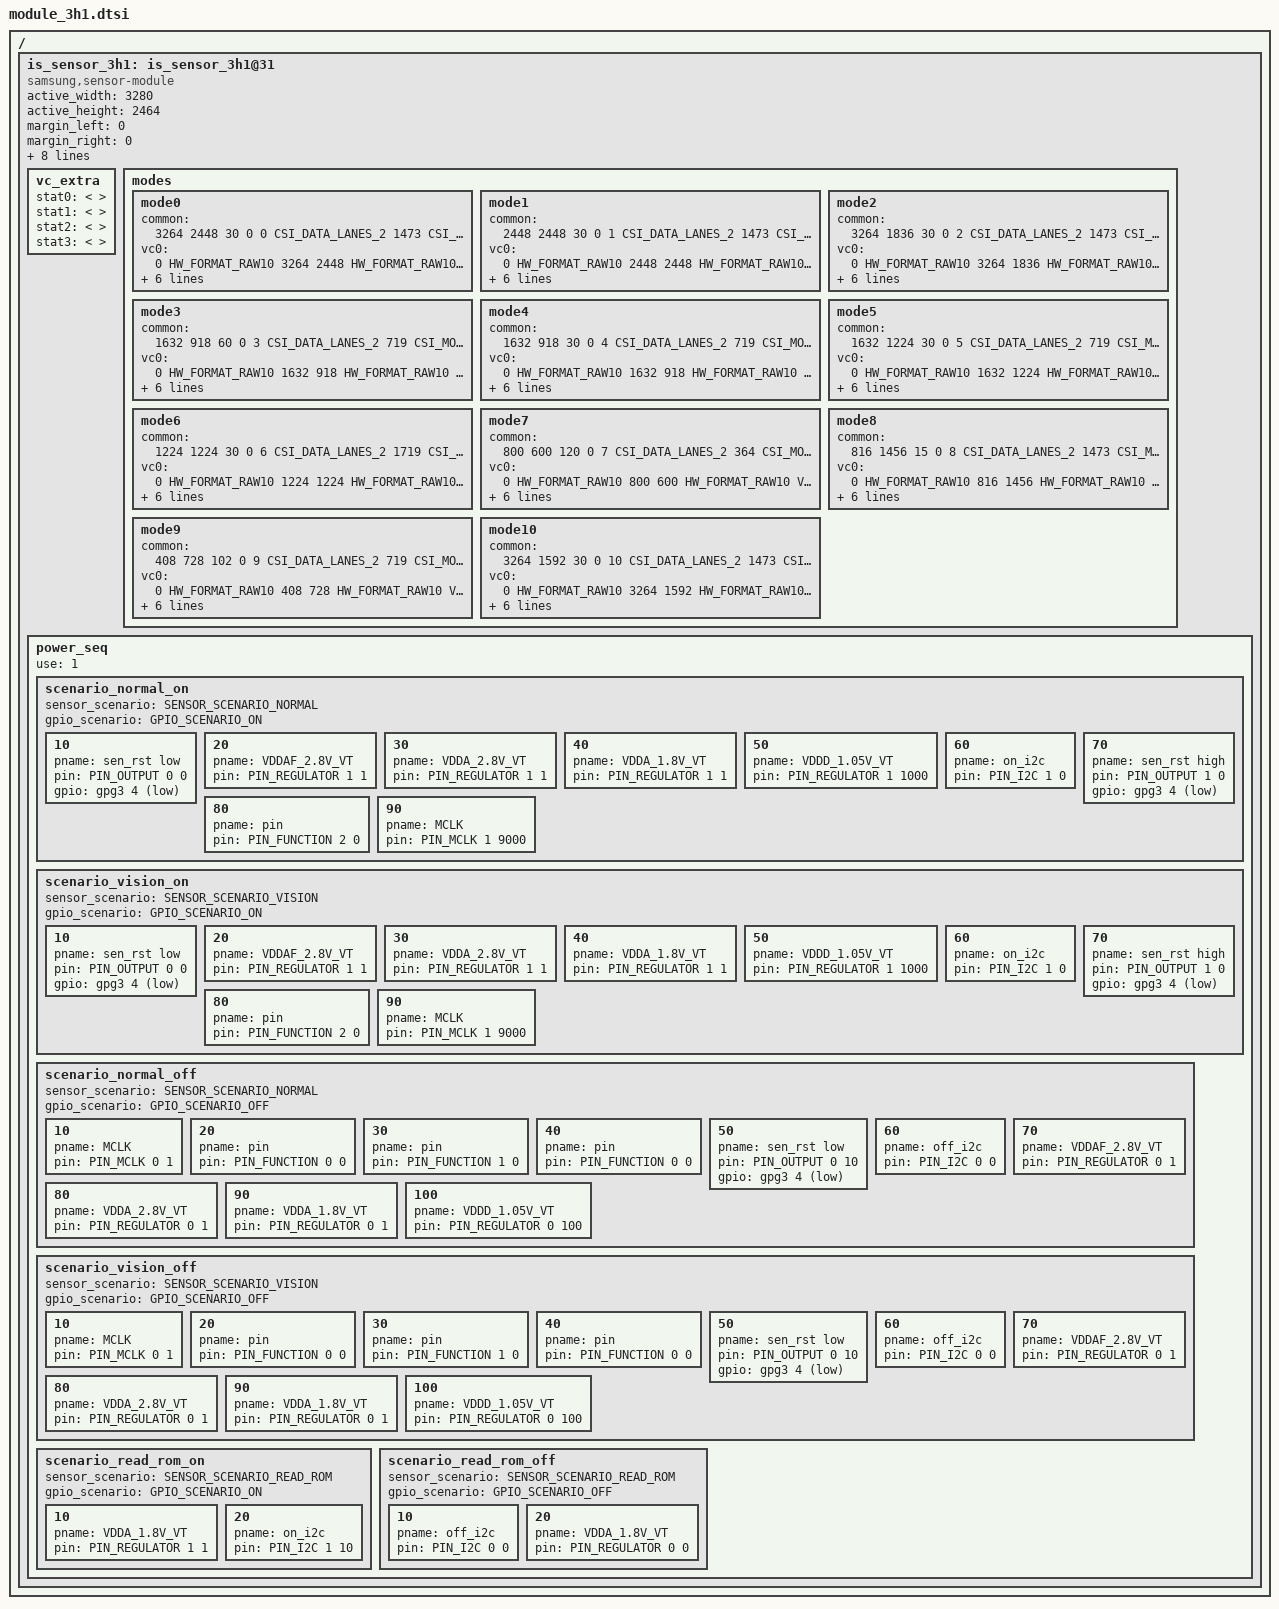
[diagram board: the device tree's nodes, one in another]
/*
 * SAMSUNG EXYNOSxxxx board camera device tree source
 *
 * Copyright (c) 2020 Samsung Electronics Co., Ltd.
 *		http://www.samsung.com
 *
 * This program is free software; you can redistribute it and/or modify
 * it under the terms of the GNU General Public License version 2 as
 * published by the Free Software Foundation.
 */

#include <dt-bindings/camera/exynos_is_dt.h>

/ {
	fragment@camera {
		target-path = "/";
		__overlay__ {
			is_sensor_3h1: is_sensor_3h1@31 {
				compatible = "samsung,sensor-module";

				/* common */
				active_width = <3280>;
				active_height = <2464>;
				margin_left = <0>;
				margin_right = <0>;
				margin_top = <0>;
				margin_bottom = <0>;
				max_framerate = <120>;
				bitwidth = <10>;
				use_retention_mode = <SENSOR_RETENTION_INACTIVE>;
				sensor_maker = "SLSI";
				sensor_name = "3H1";
				setfile_name = "setfile_3h1.bin";

				status = "okay";

				vc_extra {
					/* ex) statX = <stat_type, sensor_mode, max_width, max_height, max_element> */
					stat0 = </* not avaliable */>;		/* VC_BUF_DATA_TYPE_SENSOR_STAT1 */
					stat1 = </* not avaliable */>;		/* VC_BUF_DATA_TYPE_GENERAL_STAT1 */
					stat2 = </* not avaliable */>;		/* VC_BUF_DATA_TYPE_SENSOR_STAT2 */
					stat3 = </* not avaliable */>;		/* VC_BUF_DATA_TYPE_GENERAL_STAT2 */
				};

				/* sensor modes */
				modes {
						/* common = <width, height, fps, settle, mode, lane, speed, interleave, lrte, pd_mode> */
						/* vcX = <map, hwformat, width, height, hwformat, type, width, height> */
					mode0 {
						common = <3264 2448 30 0 0 CSI_DATA_LANES_2 1473 CSI_MODE_VC_DT LRTE_DISABLE PD_NONE EX_NONE>;
						vc0 = </* in */ 0 HW_FORMAT_RAW10 3264 2448	/* out */ HW_FORMAT_RAW10 VC_NOTHING 3264 2448>;
						vc1 = </* in */ 1 HW_FORMAT_UNKNOWN 0 0		/* out */ HW_FORMAT_UNKNOWN VC_NOTHING 0 0>;
						vc2 = </* in */ 0 HW_FORMAT_EMBEDDED_8BIT 0 0	/* out */ HW_FORMAT_EMBEDDED_8BIT VC_NOTHING 0 0>;
						vc3 = </* in */ 3 HW_FORMAT_UNKNOWN 0 0		/* out */ HW_FORMAT_UNKNOWN VC_NOTHING 0 0>;
					};
					mode1 {
						common = <2448 2448 30 0 1 CSI_DATA_LANES_2 1473 CSI_MODE_VC_DT LRTE_DISABLE PD_NONE EX_NONE>;
						vc0 = </* in */ 0 HW_FORMAT_RAW10 2448 2448	/* out */ HW_FORMAT_RAW10 VC_NOTHING 2448 2448>;
						vc1 = </* in */ 1 HW_FORMAT_UNKNOWN 0 0		/* out */ HW_FORMAT_UNKNOWN VC_NOTHING 0 0>;
						vc2 = </* in */ 0 HW_FORMAT_EMBEDDED_8BIT 0 0	/* out */ HW_FORMAT_EMBEDDED_8BIT VC_NOTHING 0 0>;
						vc3 = </* in */ 3 HW_FORMAT_UNKNOWN 0 0		/* out */ HW_FORMAT_UNKNOWN VC_NOTHING 0 0>;
					};
					mode2 {
						common = <3264 1836 30 0 2 CSI_DATA_LANES_2 1473 CSI_MODE_VC_DT LRTE_DISABLE PD_NONE EX_NONE>;
						vc0 = </* in */ 0 HW_FORMAT_RAW10 3264 1836	/* out */ HW_FORMAT_RAW10 VC_NOTHING 3264 1836>;
						vc1 = </* in */ 1 HW_FORMAT_UNKNOWN 0 0		/* out */ HW_FORMAT_UNKNOWN VC_NOTHING 0 0>;
						vc2 = </* in */ 0 HW_FORMAT_EMBEDDED_8BIT 0 0	/* out */ HW_FORMAT_EMBEDDED_8BIT VC_NOTHING 0 0>;
						vc3 = </* in */ 3 HW_FORMAT_UNKNOWN 0 0		/* out */ HW_FORMAT_UNKNOWN VC_NOTHING 0 0>;
					};
					mode3 {
						common = <1632 918 60 0 3 CSI_DATA_LANES_2 719 CSI_MODE_VC_DT LRTE_DISABLE PD_NONE EX_NONE>;
						vc0 = </* in */ 0 HW_FORMAT_RAW10 1632 918	/* out */ HW_FORMAT_RAW10 VC_NOTHING 1632 918>;
						vc1 = </* in */ 1 HW_FORMAT_UNKNOWN 0 0		/* out */ HW_FORMAT_UNKNOWN VC_NOTHING 0 0>;
						vc2 = </* in */ 0 HW_FORMAT_EMBEDDED_8BIT 0 0	/* out */ HW_FORMAT_EMBEDDED_8BIT VC_NOTHING 0 0>;
						vc3 = </* in */ 3 HW_FORMAT_UNKNOWN 0 0		/* out */ HW_FORMAT_UNKNOWN VC_NOTHING 0 0>;
					};
					mode4 {
						common = <1632 918 30 0 4 CSI_DATA_LANES_2 719 CSI_MODE_VC_DT LRTE_DISABLE PD_NONE EX_NONE>;
						vc0 = </* in */ 0 HW_FORMAT_RAW10 1632 918	/* out */ HW_FORMAT_RAW10 VC_NOTHING 1632 918>;
						vc1 = </* in */ 1 HW_FORMAT_UNKNOWN 0 0		/* out */ HW_FORMAT_UNKNOWN VC_NOTHING 0 0>;
						vc2 = </* in */ 0 HW_FORMAT_EMBEDDED_8BIT 0 0	/* out */ HW_FORMAT_EMBEDDED_8BIT VC_NOTHING 0 0>;
						vc3 = </* in */ 3 HW_FORMAT_UNKNOWN 0 0		/* out */ HW_FORMAT_UNKNOWN VC_NOTHING 0 0>;
					};
					mode5 {
						common = <1632 1224 30 0 5 CSI_DATA_LANES_2 719 CSI_MODE_VC_DT LRTE_DISABLE PD_NONE EX_NONE>;
						vc0 = </* in */ 0 HW_FORMAT_RAW10 1632 1224	/* out */ HW_FORMAT_RAW10 VC_NOTHING 1632 1224>;
						vc1 = </* in */ 1 HW_FORMAT_UNKNOWN 0 0		/* out */ HW_FORMAT_UNKNOWN VC_NOTHING 0 0>;
						vc2 = </* in */ 0 HW_FORMAT_EMBEDDED_8BIT 0 0	/* out */ HW_FORMAT_EMBEDDED_8BIT VC_NOTHING 0 0>;
						vc3 = </* in */ 3 HW_FORMAT_UNKNOWN 0 0		/* out */ HW_FORMAT_UNKNOWN VC_NOTHING 0 0>;
					};
					mode6 {
						common = <1224 1224 30 0 6 CSI_DATA_LANES_2 1719 CSI_MODE_VC_DT LRTE_DISABLE PD_NONE EX_NONE>;
						vc0 = </* in */ 0 HW_FORMAT_RAW10 1224 1224	/* out */ HW_FORMAT_RAW10 VC_NOTHING 1224 1224>;
						vc1 = </* in */ 1 HW_FORMAT_UNKNOWN 0 0		/* out */ HW_FORMAT_UNKNOWN VC_NOTHING 0 0>;
						vc2 = </* in */ 0 HW_FORMAT_EMBEDDED_8BIT 0 0	/* out */ HW_FORMAT_EMBEDDED_8BIT VC_NOTHING 0 0>;
						vc3 = </* in */ 3 HW_FORMAT_UNKNOWN 0 0		/* out */ HW_FORMAT_UNKNOWN VC_NOTHING 0 0>;
					};
					mode7 {
						common = <800 600 120 0 7 CSI_DATA_LANES_2 364 CSI_MODE_VC_DT LRTE_DISABLE PD_NONE EX_NONE>;
						vc0 = </* in */ 0 HW_FORMAT_RAW10 800 600	/* out */ HW_FORMAT_RAW10 VC_NOTHING 800 600>;
						vc1 = </* in */ 1 HW_FORMAT_UNKNOWN 0 0		/* out */ HW_FORMAT_UNKNOWN VC_NOTHING 0 0>;
						vc2 = </* in */ 0 HW_FORMAT_EMBEDDED_8BIT 0 0	/* out */ HW_FORMAT_EMBEDDED_8BIT VC_NOTHING 0 0>;
						vc3 = </* in */ 3 HW_FORMAT_UNKNOWN 0 0		/* out */ HW_FORMAT_UNKNOWN VC_NOTHING 0 0>;
					};
					mode8 {
						common = <816 1456 15 0 8 CSI_DATA_LANES_2 1473 CSI_MODE_VC_DT LRTE_DISABLE PD_NONE EX_NONE>;
						vc0 = </* in */ 0 HW_FORMAT_RAW10 816 1456	/* out */ HW_FORMAT_RAW10 VC_NOTHING 816 1456>;
						vc1 = </* in */ 1 HW_FORMAT_UNKNOWN 0 0		/* out */ HW_FORMAT_UNKNOWN VC_NOTHING 0 0>;
						vc2 = </* in */ 0 HW_FORMAT_EMBEDDED_8BIT 0 0	/* out */ HW_FORMAT_EMBEDDED_8BIT VC_NOTHING 0 0>;
						vc3 = </* in */ 3 HW_FORMAT_UNKNOWN 0 0		/* out */ HW_FORMAT_UNKNOWN VC_NOTHING 0 0>;
					};
					mode9 {
						common = <408 728 102 0 9 CSI_DATA_LANES_2 719 CSI_MODE_VC_DT LRTE_DISABLE PD_NONE EX_NONE>;
						vc0 = </* in */ 0 HW_FORMAT_RAW10 408 728	/* out */ HW_FORMAT_RAW10 VC_NOTHING 408 728>;
						vc1 = </* in */ 1 HW_FORMAT_UNKNOWN 0 0		/* out */ HW_FORMAT_UNKNOWN VC_NOTHING 0 0>;
						vc2 = </* in */ 0 HW_FORMAT_EMBEDDED_8BIT 0 0	/* out */ HW_FORMAT_EMBEDDED_8BIT VC_NOTHING 0 0>;
						vc3 = </* in */ 3 HW_FORMAT_UNKNOWN 0 0		/* out */ HW_FORMAT_UNKNOWN VC_NOTHING 0 0>;
					};
					mode10 {
						common = <3264 1592 30 0 10 CSI_DATA_LANES_2 1473 CSI_MODE_VC_DT LRTE_DISABLE PD_NONE EX_NONE>;
						vc0 = </* in */ 0 HW_FORMAT_RAW10 3264 1592	/* out */ HW_FORMAT_RAW10 VC_NOTHING 3264 1592>;
						vc1 = </* in */ 1 HW_FORMAT_UNKNOWN 0 0		/* out */ HW_FORMAT_UNKNOWN VC_NOTHING 0 0>;
						vc2 = </* in */ 0 HW_FORMAT_EMBEDDED_8BIT 0 0	/* out */ HW_FORMAT_EMBEDDED_8BIT VC_NOTHING 0 0>;
						vc3 = </* in */ 3 HW_FORMAT_UNKNOWN 0 0		/* out */ HW_FORMAT_UNKNOWN VC_NOTHING 0 0>;
					};
				};


				power_seq {
					use = <1>;
					scenario_normal_on {
						sensor_scenario = <SENSOR_SCENARIO_NORMAL>;
						gpio_scenario = <GPIO_SCENARIO_ON>;

						/* A start node number should be over the 10 for reserved number 0~9. */
						/* pname = "name"; pin = <act value dealy voltage>; gpio = <gpx# # 0x1>; */
						10 { pname = "sen_rst low"; pin = <PIN_OUTPUT 0 0>; gpio = <&gpg3 4 0x1>; };
						20 { pname = "VDDAF_2.8V_VT"; pin = <PIN_REGULATOR 1 1>; };
						30 { pname = "VDDA_2.8V_VT"; pin = <PIN_REGULATOR 1 1>; };
						40 { pname = "VDDA_1.8V_VT"; pin = <PIN_REGULATOR 1 1>; };
						50 { pname = "VDDD_1.05V_VT"; pin = <PIN_REGULATOR 1 1000>; };
						60 { pname = "on_i2c"; pin = <PIN_I2C 1 0>; };
						70 { pname = "sen_rst high"; pin = <PIN_OUTPUT 1 0>; gpio = <&gpg3 4 0x1>; };
						80 { pname = "pin"; pin = <PIN_FUNCTION 2 0>; };
						90 { pname = "MCLK"; pin = <PIN_MCLK 1 9000>; };
					};

					scenario_vision_on {
						sensor_scenario = <SENSOR_SCENARIO_VISION>;
						gpio_scenario = <GPIO_SCENARIO_ON>;

						/* A start node number should be over the 10 for reserved number 0~9. */
						/* pname = "name"; pin = <act value dealy voltage>; gpio = <gpx# # 0x1>; */
						10 { pname = "sen_rst low"; pin = <PIN_OUTPUT 0 0>; gpio = <&gpg3 4 0x1>; };
						20 { pname = "VDDAF_2.8V_VT"; pin = <PIN_REGULATOR 1 1>; };
						30 { pname = "VDDA_2.8V_VT"; pin = <PIN_REGULATOR 1 1>; };
						40 { pname = "VDDA_1.8V_VT"; pin = <PIN_REGULATOR 1 1>; };
						50 { pname = "VDDD_1.05V_VT"; pin = <PIN_REGULATOR 1 1000>; };
						60 { pname = "on_i2c"; pin = <PIN_I2C 1 0>; };
						70 { pname = "sen_rst high"; pin = <PIN_OUTPUT 1 0>; gpio = <&gpg3 4 0x1>; };
						80 { pname = "pin"; pin = <PIN_FUNCTION 2 0>; };
						90 { pname = "MCLK"; pin = <PIN_MCLK 1 9000>; };
					};

					scenario_normal_off {
						sensor_scenario = <SENSOR_SCENARIO_NORMAL>;
						gpio_scenario = <GPIO_SCENARIO_OFF>;

						/* A start node number should be over the 10 for reserved number 0~9. */
						/* pname = "name"; pin = <act value dealy voltage>; gpio = <gpx# # 0x1>; */

						10 { pname = "MCLK"; pin = <PIN_MCLK 0 1>; };
						20 { pname = "pin"; pin = <PIN_FUNCTION 0 0>; };
						30 { pname = "pin"; pin = <PIN_FUNCTION 1 0>; };
						40 { pname = "pin"; pin = <PIN_FUNCTION 0 0>; };
						50 { pname = "sen_rst low"; pin = <PIN_OUTPUT 0 10>; gpio = <&gpg3 4 0x1>; };
						60 { pname = "off_i2c"; pin = <PIN_I2C 0 0>; };
						70 { pname = "VDDAF_2.8V_VT"; pin = <PIN_REGULATOR 0 1>; };
						80 { pname = "VDDA_2.8V_VT"; pin = <PIN_REGULATOR 0 1>; };
						90 { pname = "VDDA_1.8V_VT"; pin = <PIN_REGULATOR 0 1>; };
						100 { pname = "VDDD_1.05V_VT"; pin = <PIN_REGULATOR 0 100>; };
					};

					scenario_vision_off {
						sensor_scenario = <SENSOR_SCENARIO_VISION>;
						gpio_scenario = <GPIO_SCENARIO_OFF>;

						/* A start node number should be over the 10 for reserved number 0~9. */
						/* pname = "name"; pin = <act value dealy voltage>; gpio = <gpx# # 0x1>; */

						10 { pname = "MCLK"; pin = <PIN_MCLK 0 1>; };
						20 { pname = "pin"; pin = <PIN_FUNCTION 0 0>; };
						30 { pname = "pin"; pin = <PIN_FUNCTION 1 0>; };
						40 { pname = "pin"; pin = <PIN_FUNCTION 0 0>; };
						50 { pname = "sen_rst low"; pin = <PIN_OUTPUT 0 10>; gpio = <&gpg3 4 0x1>; };
						60 { pname = "off_i2c"; pin = <PIN_I2C 0 0>; };
						70 { pname = "VDDAF_2.8V_VT"; pin = <PIN_REGULATOR 0 1>; };
						80 { pname = "VDDA_2.8V_VT"; pin = <PIN_REGULATOR 0 1>; };
						90 { pname = "VDDA_1.8V_VT"; pin = <PIN_REGULATOR 0 1>; };
						100 { pname = "VDDD_1.05V_VT"; pin = <PIN_REGULATOR 0 100>; };
					};

					scenario_read_rom_on {
						sensor_scenario = <SENSOR_SCENARIO_READ_ROM>;
						gpio_scenario = <GPIO_SCENARIO_ON>;

						/* A start node number should be over the 10 for reserved number 0~9. */
						/* pname = "name"; pin = <act value dealy voltage>; gpio = <gpx# # 0x1>; */
						10 { pname = "VDDA_1.8V_VT"; pin = <PIN_REGULATOR 1 1>; };
						20 { pname = "on_i2c"; pin = <PIN_I2C 1 10>; };
					};

					scenario_read_rom_off {
						sensor_scenario = <SENSOR_SCENARIO_READ_ROM>;
						gpio_scenario = <GPIO_SCENARIO_OFF>;

						/* A start node number should be over the 10 for reserved number 0~9. */
						/* pname = "name"; pin = <act value dealy voltage>; gpio = <gpx# # 0x1>; */
						10 { pname = "off_i2c"; pin = <PIN_I2C 0 0>; };
						20 { pname = "VDDA_1.8V_VT"; pin = <PIN_REGULATOR 0 0>; };
					};
				};
			};
		}; /* end of __overlay__ */
	}; /* end of fragment */
}; /* end of root */
